# STC32G144K246 register map
Vendor: STC; File version: 2.0
Registers are 8-bit, read-write, no defined reset value unless marked. A register's access mark holds for its fields unless they carry their own. Offsets are from the block's base; [hi:lo] are bit positions.

## PinMux — 各外设引脚选择
Base 0x007EFD69
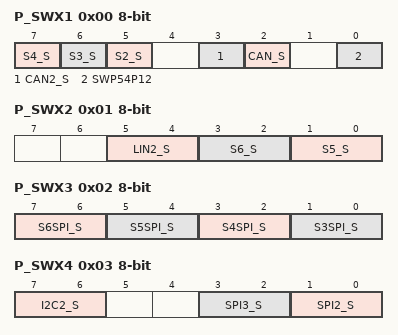
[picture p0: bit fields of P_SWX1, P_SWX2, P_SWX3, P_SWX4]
0x00 P_SWX1 — 功能脚切换扩展寄存器1
  [7] S4_S — 串口4 功能脚选择位
  [6] S3_S — 串口3 功能脚选择位
  [5] S2_S — 串口2 功能脚选择位
  [3] CAN2_S — CAN2 功能脚选择位
  [2] CAN_S — CAN1 功能脚选择位
  [0] SWP54P12 — P5.4 和P1.2 管脚数字功能切换
    0=P5.4 外部端口的数组功能为P5.4 口相关的数字功能; 1=P5.4 外部端口的数组功能为P1.2 口相关的数字功能
0x01 P_SWX2 — 功能脚切换扩展寄存器2
  [5:4] LIN2_S — LIN2 功能脚选择位
    0=LIN2_RX：P0.6；LIN2_TX：P0.7; 1=LIN2_RX：P2.6；LIN2_TX：P2.7; 2=LIN2_RX：P6.2；LIN2_TX：P6.3; 3=LIN2_RX：P8.4；LIN2_TX：P8.5
  [3:2] S6_S — 串口6 功能脚选择位
    0=RxD6：P0.6；TxD6：P0.7; 1=RxD6：P6.2；TxD6：P6.3; 2=RxD6：P3.2；TxD6：P3.3; 3=RxD6：P2.6；TxD6：P2.7
  [1:0] S5_S — 串口5 功能脚选择位
    0=RxD5：P0.4；TxD5：P0.5; 1=RxD5：P4.0；TxD5：P4.1; 2=RxD5：P1.4；TxD5：P1.5; 3=RxD5：P2.0；TxD5：P2.1
0x02 P_SWX3 — 功能脚切换扩展寄存器3
  [7:6] S6SPI_S — USART6 的SPI 功能脚选择位
    0=S6SS：P2.2；S6MOSI：P2.3；S6MISO：P2.4；S6SCLK：P2.5; 1=S6SS：P7.0；S6MOSI：P7.1；S6MISO：P7.2；S6SCLK：P7.3; 2=S6SS：P8.4；S6MOSI：P8.5；S6MISO：P8.6；S6SCLK：P8.7; 3=S6SS：P9.4；S6MOSI：P9.5；S6MISO：P9.6；S6SCLK：P9.7
  [5:4] S5SPI_S — USART5 的SPI 功能脚选择位
    0=S5SS：P2.2；S5MOSI：P2.3；S5MISO：P2.4；S5SCLK：P2.5; 1=S5SS：P7.0；S5MOSI：P7.1；S5MISO：P7.2；S5SCLK：P7.3; 2=S5SS：P8.4；S5MOSI：P8.5；S5MISO：P8.6；S5SCLK：P8.7; 3=S5SS：P9.0；S5MOSI：P9.1；S5MISO：P9.2；S5SCLK：P9.3
  [3:2] S4SPI_S — USART4 的SPI 功能脚选择位
    0=S4SS：P6.4；S4MOSI：P6.5；S4MISO：P6.6；S4SCLK：P6.7; 1=S4SS：P0.2；S4MOSI：P0.3；S4MISO：P0.4；S4SCLK：P0.5; 2=S4SS：PB.1；S4MOSI：PB.2；S4MISO：PB.3；S4SCLK：PB.4; 3=S4SS：P7.0；S4MOSI：P7.1；S4MISO：P7.2；S4SCLK：P7.3
  [1:0] S3SPI_S — USART3 的SPI 功能脚选择位
    0=S3SS：P6.4；S3MOSI：P6.5；S3MISO：P6.6；S3SCLK：P6.7; 1=S3SS：P0.2；S3MOSI：P0.3；S3MISO：P0.4；S3SCLK：P0.5; 2=S3SS：PB.1；S3MOSI：PB.2；S3MISO：PB.3；S3SCLK：PB.4; 3=S3SS：P9.4；S3MOSI：P9.5；S3MISO：P9.6；S3SCLK：P9.7
0x03 P_SWX4 — 功能脚切换扩展寄存器4
  [7:6] I2C2_S — I2C2 功能脚选择位SPI2_S[1:0]：SPI2 功能脚选择位
    0=SCL2：P2.7；SDA2：P2.6; 1=SCL2：P3.7；SDA2：P3.6; 2=SCL2：P1.7；SDA2：P1.6; 3=SCL2：P6.1；SDA2：P6.0
  [3:2] SPI3_S — SPI3 功能脚选择位
    0=SS3：P2.2；MOSI3：P2.3；MISO3：P2.4；SCLK3：P2.5; 1=SS3：P7.0；MOSI3：P7.1；MISO3：P7.2；SCLK3：P7.3; 2=SS3：P8.4；MOSI3：P8.5；MISO3：P8.6；SCLK3：P8.7; 3=SS3：P9.0；MOSI3：P9.1；MISO3：P9.2；SCLK3：P9.3
  [1:0] SPI2_S — SPI2 功能脚选择位
    0=SS2：P6.4；MOSI2：P6.5；MISO2：P6.6；SCLK2：P6.7; 1=SS2：P0.2；MOSI2：P0.3；MISO2：P0.4；SCLK2：P0.5; 2=SS2：PB.1；MOSI2：PB.2；MISO2：PB.3；SCLK2：PB.4; 3=SS2：P8.0；MOSI2：P8.1；MISO2：P8.2；SCLK2：P8.3
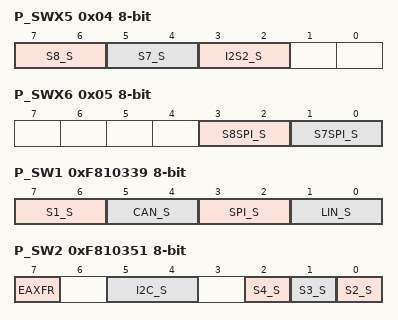
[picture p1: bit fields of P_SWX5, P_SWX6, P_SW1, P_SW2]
0x04 P_SWX5 — 功能脚切换扩展寄存器5
  [7:6] S8_S — 串口8 功能脚选择位
    0=RxD8：P5.2；TxD8：P5.3; 1=RxD8：PA.6；TxD8：PA.7; 2=RxD8：P9.2；TxD8：P9.3; 3=RxD8：P6.0；TxD8：P6.1
  [5:4] S7_S — 串口7 功能脚选择位
    0=RxD7：P5.0；TxD7：P5.1; 1=RxD7：PA.4；TxD7：PA.5; 2=RxD7：P9.0；TxD7：P9.1; 3=RxD7：P1.2；TxD7：P1.3
  [3:2] I2S2_S — I2S2 功能脚选择位
0x05 P_SWX6 — 功能脚切换扩展寄存器6
  [3:2] S8SPI_S — USART8 的SPI 功能脚选择位
    0=S8SS：P5.0；S8MOSI：P5.1；S8MISO：P5.2；S8SCLK：P5.3; 1=S8SS：PA.4；S8MOSI：PA.5；S8MISO：PA.6；S8SCLK：PA.7; 2=S8SS：P7.4；S8MOSI：P7.5；S8MISO：P7.6；S8SCLK：P7.7; 3=S8SS：P6.0；S8MOSI：P6.1；S8MISO：P6.2；S8SCLK：P6.3
  [1:0] S7SPI_S — USART7 的SPI 功能脚选择位
    0=S7SS：P5.0；S7MOSI：P5.1；S7MISO：P5.2；S7SCLK：P5.3; 1=S7SS：PA.4；S7MOSI：PA.5；S7MISO：PA.6；S7SCLK：PA.7; 2=S7SS：P7.4；S7MOSI：P7.5；S7MISO：P7.6；S7SCLK：P7.7; 3=S7SS：PC.0；S7MOSI：PC.1；S7MISO：PC.2；S7SCLK：PC.3
0x06 P_SWX7
0xF810339 P_SW1 — 外设端口切换寄存器1
  [7:6] S1_S — 串口1 功能脚选择位
    0=RxD：P3.0；TxD：P3.1; 1=RxD：P3.6；TxD：P3.7; 2=RxD：P1.6；TxD：P1.7; 3=RxD：P4.3；TxD：P4.4
  [5:4] CAN_S — CAN1 功能脚选择位
  [3:2] SPI_S — SPI 功能脚选择位
    0=SS：P1.2；MOSI：P1.3；MISO：P1.4；SCLK：P1.5; 1=SS：P2.2；MOSI：P2.3；MISO：P2.4；SCLK：P2.5; 2=SS：P5.4；MOSI：P4.0；MISO：P4.1；SCLK：P4.3; 3=SS：P3.5；MOSI：P3.4；MISO：P3.3；SCLK：P3.2
  [1:0] LIN_S — LIN 功能脚选择位
    0=LIN_RX：P0.2；LIN_TX：P0.3; 1=LIN_RX：P5.2；LIN_TX：P5.3; 2=LIN_RX：P4.6；LIN_TX：P4.7; 3=LIN_RX：P7.2；LIN_TX：P7.3
0xF810351 P_SW2 — 外设端口切换寄存器2
  [7] EAXFR — 扩展RAM 区特殊功能寄存器（XFR）访问控制寄存器
    0=禁止访问XFR; 1=使能访问XFR。
  [5:4] I2C_S — I2C 功能脚选择位
    0=SCL：P1.5；SDA：P1.4; 1=SCL：P2.5；SDA：P2.4; 2=SCL：P7.7；SDA：P7.6; 3=SCL：P3.2；SDA：P3.3
  [2] S4_S — 串口4 功能脚选择位
  [1] S3_S — 串口3 功能脚选择位
  [0] S2_S — 串口2 功能脚选择位
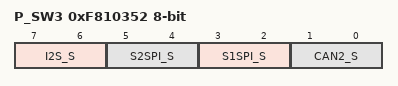
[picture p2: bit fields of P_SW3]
0xF810352 P_SW3 — 外设端口切换寄存器2
  [7:6] I2S_S — I2S 功能脚选择位
  [5:4] S2SPI_S — USART2 的SPI 功能脚选择位
    0=S2SS：P1.2；S2MOSI：P1.3；S2MISO：P1.4；S2SCLK：P1.5; 1=S2SS：P2.2；S2MOSI：P2.3；S2MISO：P2.4；S2SCLK：P2.5; 2=S2SS：P5.4；S2MOSI：P4.0；S2MISO：P4.1；S2SCLK：P4.3; 3=S2SS：P7.4；S2MOSI：P7.5；S2MISO：P7.6；S2SCLK：P7.7
  [3:2] S1SPI_S — USART1 的SPI 功能脚选择位
    0=S1SS：P1.2；S1MOSI：P1.3；S1MISO：P1.4；S1SCLK：P1.5; 1=S1SS：P2.2；S1MOSI：P2.3；S1MISO：P2.4；S1SCLK：P2.5; 2=S1SS：P5.4；S1MOSI：P4.0；S1MISO：P4.1；S1SCLK：P4.3; 3=S1SS：P6.4；S1MOSI：P6.5；S1MISO：P6.6；S1SCLK：P6.7
  [1:0] CAN2_S — CAN2 功能脚选择位
0xF810356 P_SW4 — 外设端口切换寄存器4
  [1:0] QSPI_S — QSPI 功能脚选择位
    0=QSPINCS = P1.2；QSPIIO0 = P1.3；QSPIIO1 = P1.4；QSPIIO2 = P1.1；QSPIIO3 = P1.0；QSPICLK = P1.5; 1=QSPINCS = P5.4；QSPIIO0 = P4.0；QSPIIO1 = P4.1；QSPIIO2 = P4.6；QSPIIO3 = P4.7；QSPICLK = P4.3; 2=QSPINCS = P7.5；QSPIIO0 = P7.0；QSPIIO1 = P7.2；QSPIIO2 = P7.3；QSPIIO3 = P7.4；QSPICLK = P7.1; 3=QSPINCS = -；QSPIIO0 = -；QSPIIO1 = -；QSPIIO2 = -；QSPIIO3 = -；QSPICLK = -
